# ESP32 register map
Vendor: ESPRESSIF SYSTEMS (SHANGHAI) CO., LTD.; Series: ESP32 Series; File version: 17
CPU: Xtensa LX6 r0p0, little endian, no MPU, FPU, 0 interrupt priority bits
Address unit: 32 bits
Registers are 32-bit, read-write, reset 0x0 unless marked. A register's access mark holds for its fields unless they carry their own. Offsets are from the block's base; [hi:lo] are bit positions; {n}, {i} and the like mark numbered series.

## RTC_CNTL — Real-Time Clock Control
Base 0x3FF48000
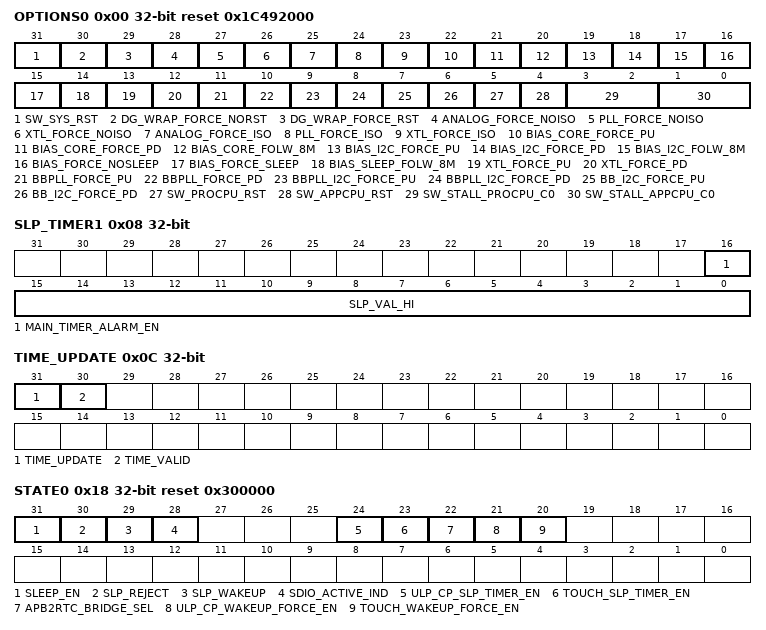
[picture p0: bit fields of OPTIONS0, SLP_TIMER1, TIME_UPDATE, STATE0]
0x00 OPTIONS0 access per field reset 0x1C492000
  [31] SW_SYS_RST wo — SW system reset
  [30] DG_WRAP_FORCE_NORST rw — digital core force no reset in deep sleep
  [29] DG_WRAP_FORCE_RST rw — digital wrap force reset in deep sleep
  [28] ANALOG_FORCE_NOISO rw
  [27] PLL_FORCE_NOISO rw
  [26] XTL_FORCE_NOISO rw
  [25] ANALOG_FORCE_ISO rw
  [24] PLL_FORCE_ISO rw
  [23] XTL_FORCE_ISO rw
  [22] BIAS_CORE_FORCE_PU rw — BIAS_CORE force power up
  [21] BIAS_CORE_FORCE_PD rw — BIAS_CORE force power down
  [20] BIAS_CORE_FOLW_8M rw — BIAS_CORE follow CK8M
  [19] BIAS_I2C_FORCE_PU rw — BIAS_I2C force power up
  [18] BIAS_I2C_FORCE_PD rw — BIAS_I2C force power down
  [17] BIAS_I2C_FOLW_8M rw — BIAS_I2C follow CK8M
  [16] BIAS_FORCE_NOSLEEP rw — BIAS_SLEEP force no sleep
  [15] BIAS_FORCE_SLEEP rw — BIAS_SLEEP force sleep
  [14] BIAS_SLEEP_FOLW_8M rw — BIAS_SLEEP follow CK8M
  [13] XTL_FORCE_PU rw — crystall force power up
  [12] XTL_FORCE_PD rw — crystall force power down
  [11] BBPLL_FORCE_PU rw — BB_PLL force power up
  [10] BBPLL_FORCE_PD rw — BB_PLL force power down
  [9] BBPLL_I2C_FORCE_PU rw — BB_PLL_I2C force power up
  [8] BBPLL_I2C_FORCE_PD rw — BB_PLL _I2C force power down
  [7] BB_I2C_FORCE_PU rw — BB_I2C force power up
  [6] BB_I2C_FORCE_PD rw — BB_I2C force power down
  [5] SW_PROCPU_RST wo — PRO CPU SW reset
  [4] SW_APPCPU_RST wo — APP CPU SW reset
  [3:2] SW_STALL_PROCPU_C0 rw — {reg_sw_stall_procpu_c1[5:0] reg_sw_stall_procpu_c0[1:0]} == 0x86 will stall PRO CPU
  [1:0] SW_STALL_APPCPU_C0 rw — {reg_sw_stall_appcpu_c1[5:0] reg_sw_stall_appcpu_c0[1:0]} == 0x86 will stall APP CPU
0x04 SLP_TIMER0
  [31:0] SLP_VAL_LO — RTC sleep timer low 32 bits
0x08 SLP_TIMER1
  [16] MAIN_TIMER_ALARM_EN — timer alarm enable bit
  [15:0] SLP_VAL_HI — RTC sleep timer high 16 bits
0x0C TIME_UPDATE access per field
  [31] TIME_UPDATE wo — Set 1: to update register with RTC timer
  [30] TIME_VALID ro — To indicate the register is updated
0x10 TIME0 ro
  [31:0] TIME_LO — RTC timer low 32 bits
0x14 TIME1 ro
  [15:0] TIME_HI — RTC timer high 16 bits
0x18 STATE0 access per field reset 0x300000
  [31] SLEEP_EN rw — sleep enable bit
  [30] SLP_REJECT rw — sleep reject bit
  [29] SLP_WAKEUP rw — sleep wakeup bit
  [28] SDIO_ACTIVE_IND ro — SDIO active indication
  [24] ULP_CP_SLP_TIMER_EN rw — ULP-coprocessor timer enable bit
  [23] TOUCH_SLP_TIMER_EN rw — touch timer enable bit
  [22] APB2RTC_BRIDGE_SEL rw — 1: APB to RTC using bridge 0: APB to RTC using sync
  [21] ULP_CP_WAKEUP_FORCE_EN rw — ULP-coprocessor force wake up
  [20] TOUCH_WAKEUP_FORCE_EN rw — touch controller force wake up
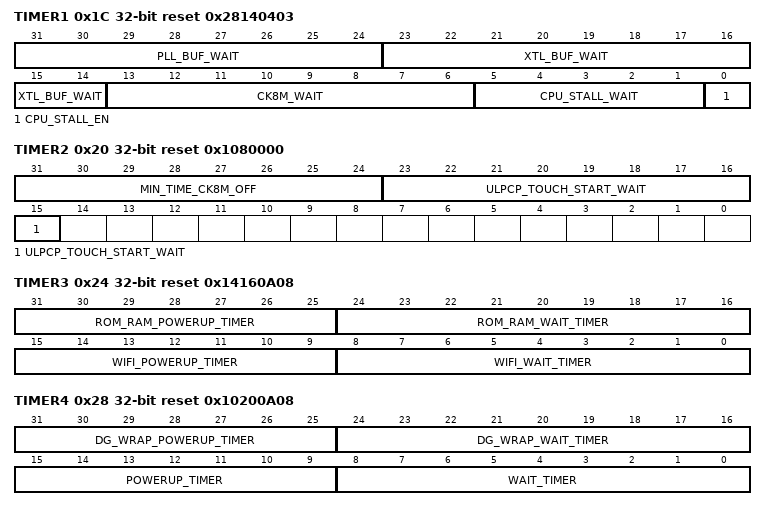
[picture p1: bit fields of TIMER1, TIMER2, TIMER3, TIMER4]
0x1C TIMER1 reset 0x28140403
  [31:24] PLL_BUF_WAIT — PLL wait cycles in slow_clk_rtc
  [23:14] XTL_BUF_WAIT — XTAL wait cycles in slow_clk_rtc
  [13:6] CK8M_WAIT — CK8M wait cycles in slow_clk_rtc
  [5:1] CPU_STALL_WAIT — CPU stall wait cycles in fast_clk_rtc
  [0] CPU_STALL_EN — CPU stall enable bit
0x20 TIMER2 reset 0x1080000
  [31:24] MIN_TIME_CK8M_OFF — minimal cycles in slow_clk_rtc for CK8M in power down state
  [23:15] ULPCP_TOUCH_START_WAIT — wait cycles in slow_clk_rtc before ULP-coprocessor / touch controller start to work
0x24 TIMER3 reset 0x14160A08
  [31:25] ROM_RAM_POWERUP_TIMER, [24:16] ROM_RAM_WAIT_TIMER, [15:9] WIFI_POWERUP_TIMER, [8:0] WIFI_WAIT_TIMER
0x28 TIMER4 reset 0x10200A08
  [31:25] DG_WRAP_POWERUP_TIMER, [24:16] DG_WRAP_WAIT_TIMER, [15:9] POWERUP_TIMER, [8:0] WAIT_TIMER
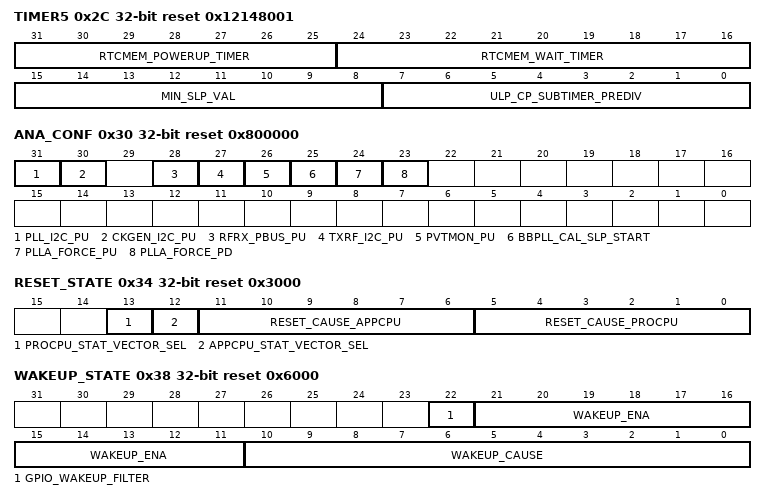
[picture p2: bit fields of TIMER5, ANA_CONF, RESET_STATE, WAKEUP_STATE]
0x2C TIMER5 reset 0x12148001
  [31:25] RTCMEM_POWERUP_TIMER
  [24:16] RTCMEM_WAIT_TIMER
  [15:8] MIN_SLP_VAL — minimal sleep cycles in slow_clk_rtc
  [7:0] ULP_CP_SUBTIMER_PREDIV
0x30 ANA_CONF reset 0x800000
  [31] PLL_I2C_PU — 1: PLL_I2C power up otherwise power down
  [30] CKGEN_I2C_PU — 1: CKGEN_I2C power up otherwise power down
  [28] RFRX_PBUS_PU — 1: RFRX_PBUS power up otherwise power down
  [27] TXRF_I2C_PU — 1: TXRF_I2C power up otherwise power down
  [26] PVTMON_PU — 1: PVTMON power up otherwise power down
  [25] BBPLL_CAL_SLP_START — start BBPLL calibration during sleep
  [24] PLLA_FORCE_PU — PLLA force power up
  [23] PLLA_FORCE_PD — PLLA force power down
0x34 RESET_STATE access per field reset 0x3000
  [13] PROCPU_STAT_VECTOR_SEL rw — PRO CPU state vector sel
  [12] APPCPU_STAT_VECTOR_SEL rw — APP CPU state vector sel
  [11:6] RESET_CAUSE_APPCPU ro — reset cause of APP CPU
  [5:0] RESET_CAUSE_PROCPU ro — reset cause of PRO CPU
0x38 WAKEUP_STATE access per field reset 0x6000
  [22] GPIO_WAKEUP_FILTER rw — enable filter for gpio wakeup event
  [21:11] WAKEUP_ENA rw — wakeup enable bitmap
  [10:0] WAKEUP_CAUSE ro
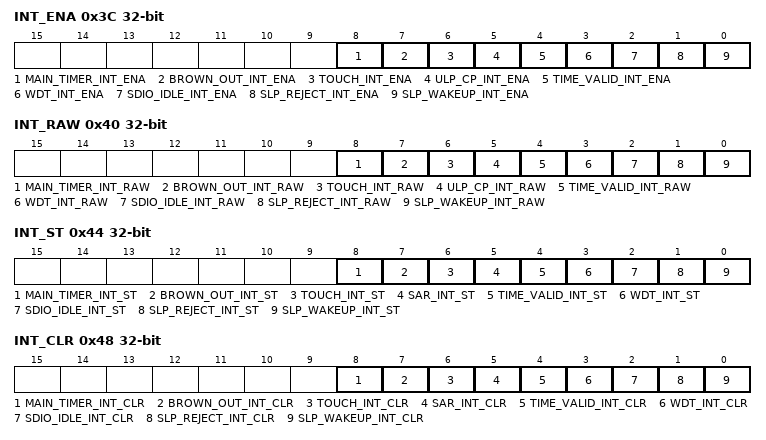
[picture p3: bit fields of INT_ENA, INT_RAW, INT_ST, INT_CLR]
0x3C INT_ENA
  [8] MAIN_TIMER_INT_ENA — enable RTC main timer interrupt
  [7] BROWN_OUT_INT_ENA — enable brown out interrupt
  [6] TOUCH_INT_ENA — enable touch interrupt
  [5] ULP_CP_INT_ENA — enable ULP-coprocessor interrupt
  [4] TIME_VALID_INT_ENA — enable RTC time valid interrupt
  [3] WDT_INT_ENA — enable RTC WDT interrupt
  [2] SDIO_IDLE_INT_ENA — enable SDIO idle interrupt
  [1] SLP_REJECT_INT_ENA — enable sleep reject interrupt
  [0] SLP_WAKEUP_INT_ENA — enable sleep wakeup interrupt
0x40 INT_RAW ro
  [8] MAIN_TIMER_INT_RAW — RTC main timer interrupt raw
  [7] BROWN_OUT_INT_RAW — brown out interrupt raw
  [6] TOUCH_INT_RAW — touch interrupt raw
  [5] ULP_CP_INT_RAW — ULP-coprocessor interrupt raw
  [4] TIME_VALID_INT_RAW — RTC time valid interrupt raw
  [3] WDT_INT_RAW — RTC WDT interrupt raw
  [2] SDIO_IDLE_INT_RAW — SDIO idle interrupt raw
  [1] SLP_REJECT_INT_RAW — sleep reject interrupt raw
  [0] SLP_WAKEUP_INT_RAW — sleep wakeup interrupt raw
0x44 INT_ST ro
  [8] MAIN_TIMER_INT_ST — RTC main timer interrupt state
  [7] BROWN_OUT_INT_ST — brown out interrupt state
  [6] TOUCH_INT_ST — touch interrupt state
  [5] SAR_INT_ST — ULP-coprocessor interrupt state
  [4] TIME_VALID_INT_ST — RTC time valid interrupt state
  [3] WDT_INT_ST — RTC WDT interrupt state
  [2] SDIO_IDLE_INT_ST — SDIO idle interrupt state
  [1] SLP_REJECT_INT_ST — sleep reject interrupt state
  [0] SLP_WAKEUP_INT_ST — sleep wakeup interrupt state
0x48 INT_CLR wo
  [8] MAIN_TIMER_INT_CLR — Clear RTC main timer interrupt state
  [7] BROWN_OUT_INT_CLR — Clear brown out interrupt state
  [6] TOUCH_INT_CLR — Clear touch interrupt state
  [5] SAR_INT_CLR — Clear ULP-coprocessor interrupt state
  [4] TIME_VALID_INT_CLR — Clear RTC time valid interrupt state
  [3] WDT_INT_CLR — Clear RTC WDT interrupt state
  [2] SDIO_IDLE_INT_CLR — Clear SDIO idle interrupt state
  [1] SLP_REJECT_INT_CLR — Clear sleep reject interrupt state
  [0] SLP_WAKEUP_INT_CLR — Clear sleep wakeup interrupt state
{0x4C+4i} STORE{i} (i=0..3)
  [31:0] SCRATCH{i} — 32-bit general purpose retention register
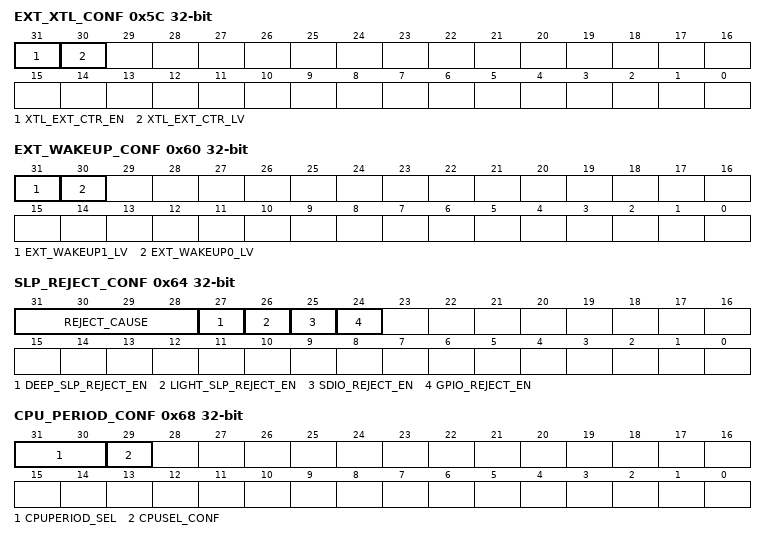
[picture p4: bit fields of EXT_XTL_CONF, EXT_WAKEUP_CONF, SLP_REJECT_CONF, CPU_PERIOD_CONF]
0x5C EXT_XTL_CONF
  [31] XTL_EXT_CTR_EN — enable control XTAL by external pads
  [30] XTL_EXT_CTR_LV — 0: power down XTAL at high level 1: power down XTAL at low level
0x60 EXT_WAKEUP_CONF
  [31] EXT_WAKEUP1_LV — 0: external wakeup at low level 1: external wakeup at high level
  [30] EXT_WAKEUP0_LV — 0: external wakeup at low level 1: external wakeup at high level
0x64 SLP_REJECT_CONF access per field
  [31:28] REJECT_CAUSE ro — sleep reject cause
  [27] DEEP_SLP_REJECT_EN rw — enable reject for deep sleep
  [26] LIGHT_SLP_REJECT_EN rw — enable reject for light sleep
  [25] SDIO_REJECT_EN rw — enable SDIO reject
  [24] GPIO_REJECT_EN rw — enable GPIO reject
0x68 CPU_PERIOD_CONF
  [31:30] CPUPERIOD_SEL
  [29] CPUSEL_CONF — CPU sel option
0x6C SDIO_ACT_CONF
  [31:22] SDIO_ACT_DNUM
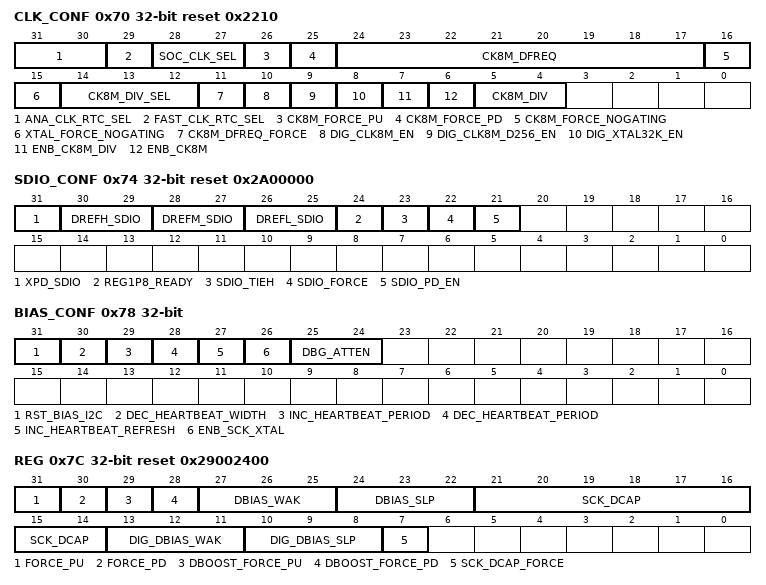
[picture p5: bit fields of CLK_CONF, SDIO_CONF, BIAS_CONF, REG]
0x70 CLK_CONF reset 0x2210
  [31:30] ANA_CLK_RTC_SEL — slow_clk_rtc sel. 0: SLOW_CK 1: CK_XTAL_32K 2: CK8M_D256_OUT
  [29] FAST_CLK_RTC_SEL — fast_clk_rtc sel. 0: XTAL div 4 1: CK8M
  [28:27] SOC_CLK_SEL — SOC clock sel. 0: XTAL 1: PLL 2: CK8M 3: APLL
  [26] CK8M_FORCE_PU — CK8M force power up
  [25] CK8M_FORCE_PD — CK8M force power down
  [24:17] CK8M_DFREQ
  [16] CK8M_FORCE_NOGATING — CK8M force no gating during sleep
  [15] XTAL_FORCE_NOGATING — XTAL force no gating during sleep
  [14:12] CK8M_DIV_SEL — divider = reg_ck8m_div_sel + 1
  [11] CK8M_DFREQ_FORCE
  [10] DIG_CLK8M_EN — enable CK8M for digital core (no relationship with RTC core)
  [9] DIG_CLK8M_D256_EN — enable CK8M_D256_OUT for digital core (no relationship with RTC core)
  [8] DIG_XTAL32K_EN — enable CK_XTAL_32K for digital core (no relationship with RTC core)
  [7] ENB_CK8M_DIV — 1: CK8M_D256_OUT is actually CK8M 0: CK8M_D256_OUT is CK8M divided by 256
  [6] ENB_CK8M — disable CK8M and CK8M_D256_OUT
  [5:4] CK8M_DIV — CK8M_D256_OUT divider. 00: div128 01: div256 10: div512 11: div1024.
0x74 SDIO_CONF access per field reset 0x2A00000
  [31] XPD_SDIO rw — SW option for XPD_SDIO_REG. Only active when reg_sdio_force = 1
  [30:29] DREFH_SDIO rw — SW option for DREFH_SDIO. Only active when reg_sdio_force = 1
  [28:27] DREFM_SDIO rw — SW option for DREFM_SDIO. Only active when reg_sdio_force = 1
  [26:25] DREFL_SDIO rw — SW option for DREFL_SDIO. Only active when reg_sdio_force = 1
  [24] REG1P8_READY ro — read only register for REG1P8_READY
  [23] SDIO_TIEH rw — SW option for SDIO_TIEH. Only active when reg_sdio_force = 1
  [22] SDIO_FORCE rw — 1: use SW option to control SDIO_REG 0: use state machine
  [21] SDIO_PD_EN rw — power down SDIO_REG in sleep. Only active when reg_sdio_force = 0
0x78 BIAS_CONF
  [31] RST_BIAS_I2C, [30] DEC_HEARTBEAT_WIDTH, [29] INC_HEARTBEAT_PERIOD, [28] DEC_HEARTBEAT_PERIOD, [27] INC_HEARTBEAT_REFRESH, [26] ENB_SCK_XTAL, [25:24] DBG_ATTEN
0x7C REG reset 0x29002400
  [31] FORCE_PU — RTC_REG force power up
  [30] FORCE_PD — RTC_REG force power down (for RTC_REG power down means decrease the voltage to 0.8v or lower )
  [29] DBOOST_FORCE_PU — RTC_DBOOST force power up
  [28] DBOOST_FORCE_PD — RTC_DBOOST force power down
  [27:25] DBIAS_WAK — RTC_DBIAS during wakeup
  [24:22] DBIAS_SLP — RTC_DBIAS during sleep
  [21:14] SCK_DCAP
  [13:11] DIG_DBIAS_WAK — DIG_REG_DBIAS during wakeup
  [10:8] DIG_DBIAS_SLP — DIG_REG_DBIAS during sleep
  [7] SCK_DCAP_FORCE
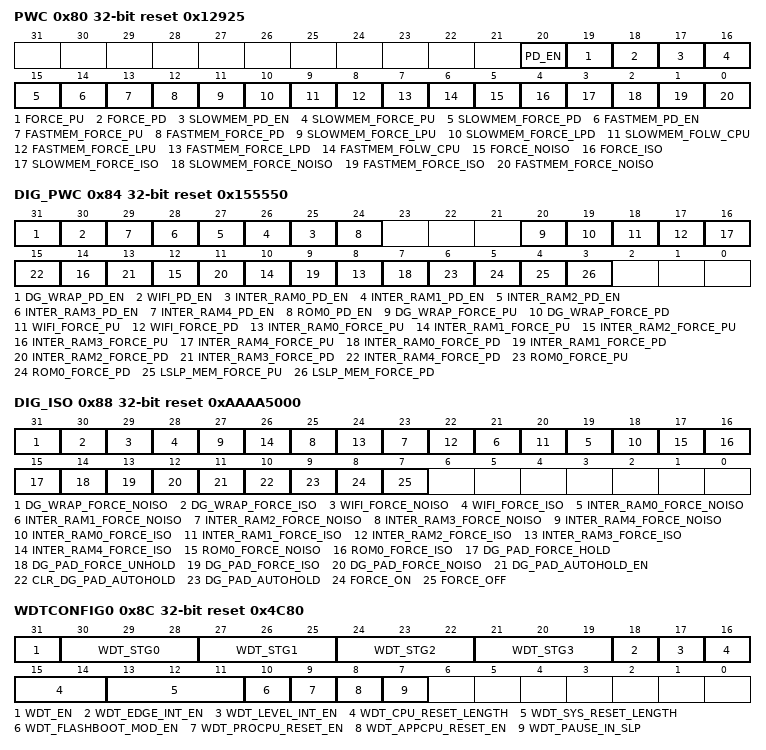
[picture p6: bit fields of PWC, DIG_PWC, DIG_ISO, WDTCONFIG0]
0x80 PWC reset 0x12925
  [20] PD_EN — enable power down rtc_peri in sleep
  [19] FORCE_PU — rtc_peri force power up
  [18] FORCE_PD — rtc_peri force power down
  [17] SLOWMEM_PD_EN — enable power down RTC memory in sleep
  [16] SLOWMEM_FORCE_PU — RTC memory force power up
  [15] SLOWMEM_FORCE_PD — RTC memory force power down
  [14] FASTMEM_PD_EN — enable power down fast RTC memory in sleep
  [13] FASTMEM_FORCE_PU — Fast RTC memory force power up
  [12] FASTMEM_FORCE_PD — Fast RTC memory force power down
  [11] SLOWMEM_FORCE_LPU — RTC memory force no PD
  [10] SLOWMEM_FORCE_LPD — RTC memory force PD
  [9] SLOWMEM_FOLW_CPU — 1: RTC memory PD following CPU 0: RTC memory PD following RTC state machine
  [8] FASTMEM_FORCE_LPU — Fast RTC memory force no PD
  [7] FASTMEM_FORCE_LPD — Fast RTC memory force PD
  [6] FASTMEM_FOLW_CPU — 1: Fast RTC memory PD following CPU 0: fast RTC memory PD following RTC state machine
  [5] FORCE_NOISO — rtc_peri force no ISO
  [4] FORCE_ISO — rtc_peri force ISO
  [3] SLOWMEM_FORCE_ISO — RTC memory force ISO
  [2] SLOWMEM_FORCE_NOISO — RTC memory force no ISO
  [1] FASTMEM_FORCE_ISO — Fast RTC memory force ISO
  [0] FASTMEM_FORCE_NOISO — Fast RTC memory force no ISO
0x84 DIG_PWC reset 0x155550
  [31] DG_WRAP_PD_EN — enable power down digital core in sleep
  [30] WIFI_PD_EN — enable power down wifi in sleep
  [n+25] INTER_RAM{n}_PD_EN (n=0..4) — enable power down internal SRAM {n} in sleep
  [24] ROM0_PD_EN — enable power down ROM in sleep
  [20] DG_WRAP_FORCE_PU — digital core force power up
  [19] DG_WRAP_FORCE_PD — digital core force power down
  [18] WIFI_FORCE_PU — wifi force power up
  [17] WIFI_FORCE_PD — wifi force power down
  [2n+8] INTER_RAM{n}_FORCE_PU (n=0..4) — internal SRAM {n} force power up
  [2n+7] INTER_RAM{n}_FORCE_PD (n=0..4) — internal SRAM {n} force power down
  [6] ROM0_FORCE_PU — ROM force power up
  [5] ROM0_FORCE_PD — ROM force power down
  [4] LSLP_MEM_FORCE_PU — memories in digital core force no PD in sleep
  [3] LSLP_MEM_FORCE_PD — memories in digital core force PD in sleep
0x88 DIG_ISO access per field reset 0xAAAA5000
  [31] DG_WRAP_FORCE_NOISO rw — digital core force no ISO
  [30] DG_WRAP_FORCE_ISO rw — digital core force ISO
  [29] WIFI_FORCE_NOISO rw
  [28] WIFI_FORCE_ISO rw
  [2n+19] INTER_RAM{n}_FORCE_NOISO rw (n=0..4) — internal SRAM {n} force no ISO
  [2n+18] INTER_RAM{n}_FORCE_ISO rw (n=0..4) — internal SRAM {n} force ISO
  [17] ROM0_FORCE_NOISO rw — ROM force no ISO
  [16] ROM0_FORCE_ISO rw — ROM force ISO
  [15] DG_PAD_FORCE_HOLD rw — digital pad force hold
  [14] DG_PAD_FORCE_UNHOLD rw — digital pad force un-hold
  [13] DG_PAD_FORCE_ISO rw — digital pad force ISO
  [12] DG_PAD_FORCE_NOISO rw — digital pad force no ISO
  [11] DG_PAD_AUTOHOLD_EN rw — digital pad enable auto-hold
  [10] CLR_DG_PAD_AUTOHOLD wo — wtite only register to clear digital pad auto-hold
  [9] DG_PAD_AUTOHOLD ro — read only register to indicate digital pad auto-hold status
  [8] FORCE_ON rw
  [7] FORCE_OFF rw
0x8C WDTCONFIG0 reset 0x4C80
  [31] WDT_EN — enable RTC WDT
  [30-3n:28-3n] WDT_STG{n} (n=0..3) — 1: interrupt stage en 2: CPU reset stage en 3: system reset stage en 4: RTC reset stage en
  [18] WDT_EDGE_INT_EN
  [17] WDT_LEVEL_INT_EN
  [16:14] WDT_CPU_RESET_LENGTH — CPU reset counter length
  [13:11] WDT_SYS_RESET_LENGTH — system reset counter length
  [10] WDT_FLASHBOOT_MOD_EN — enable WDT in flash boot
  [9] WDT_PROCPU_RESET_EN — enable WDT reset PRO CPU
  [8] WDT_APPCPU_RESET_EN — enable WDT reset APP CPU
  [7] WDT_PAUSE_IN_SLP — pause WDT in sleep
0x90 WDTCONFIG1 reset 0x1F400
  [31:0] WDT_STG0_HOLD
0x94 WDTCONFIG2 reset 0x13880
  [31:0] WDT_STG1_HOLD
0x98 WDTCONFIG3 reset 0xFFF
  [31:0] WDT_STG2_HOLD
0x9C WDTCONFIG4 reset 0xFFF
  [31:0] WDT_STG3_HOLD
0xA0 WDTFEED wo
  [31] WDT_FEED
0xA4 WDTWPROTECT reset 0x50D83AA1
  [31:0] WDT_WKEY
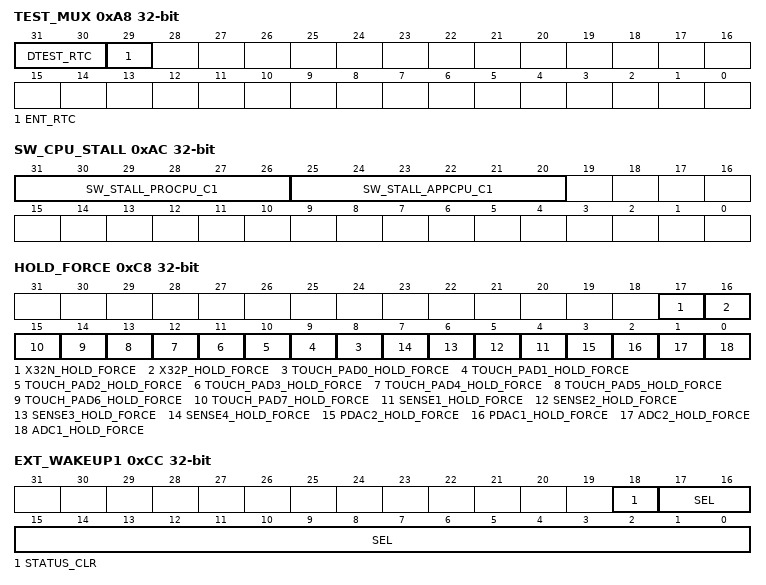
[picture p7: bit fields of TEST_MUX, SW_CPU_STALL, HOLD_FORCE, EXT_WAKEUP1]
0xA8 TEST_MUX
  [31:30] DTEST_RTC, [29] ENT_RTC
0xAC SW_CPU_STALL
  [31:26] SW_STALL_PROCPU_C1 — {reg_sw_stall_procpu_c1[5:0] reg_sw_stall_procpu_c0[1:0]} == 0x86 will stall PRO CPU
  [25:20] SW_STALL_APPCPU_C1 — {reg_sw_stall_appcpu_c1[5:0] reg_sw_stall_appcpu_c0[1:0]} == 0x86 will stall APP CPU
{0xA0+4i} STORE{i} (i=4..7)
  [31:0] SCRATCH{i} — 32-bit general purpose retention register
0xC0 LOW_POWER_ST ro
  [19] RDY_FOR_WAKEUP — 1 if RTC controller is ready to execute WAKE instruction, 0 otherwise
  [31:0] LOW_POWER_DIAG0
0xC4 DIAG1 ro
  [31:0] LOW_POWER_DIAG1
0xC8 HOLD_FORCE
  [17] X32N_HOLD_FORCE, [16] X32P_HOLD_FORCE, [n+8] TOUCH_PAD{n}_HOLD_FORCE (n=0..7), [n+3] SENSE{n}_HOLD_FORCE (n=1..4), [3] PDAC2_HOLD_FORCE, [2] PDAC1_HOLD_FORCE, [1] ADC2_HOLD_FORCE, [0] ADC1_HOLD_FORCE
0xCC EXT_WAKEUP1 access per field
  [18] STATUS_CLR wo — clear ext wakeup1 status
  [17:0] SEL rw — Bitmap to select RTC pads for ext wakeup1
0xD0 EXT_WAKEUP1_STATUS ro
  [17:0] EXT_WAKEUP1_STATUS
0xD4 BROWN_OUT access per field reset 0x13FF0000
  [31] DET ro — brown out detect
  [31] RTC_MEM_CRC_FINISH rw
  [30] ENA rw — enable brown out
  [29:27] DBROWN_OUT_THRES rw — brown out threshold
  [26] RST_ENA rw — enable brown out reset
  [30:20] RTC_MEM_CRC_LEN rw
  [25:16] RST_WAIT rw — brown out reset wait cycles
  [15] PD_RF_ENA rw — enable power down RF when brown out happens
  [14] CLOSE_FLASH_ENA rw — enable close flash when brown out happens
  [19:9] RTC_MEM_CRC_ADDR rw
  [8] RTC_MEM_CRC_START rw
  [7:0] RTC_MEM_PID_CONF rw
0x13C DATE reset 0x1604280
  [27:0] CNTL_DATE
